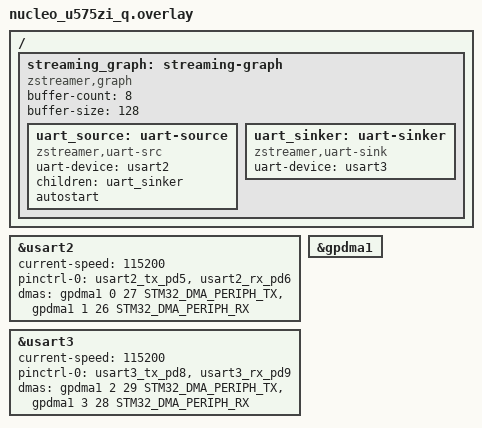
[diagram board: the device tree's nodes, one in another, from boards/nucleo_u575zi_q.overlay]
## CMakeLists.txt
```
# Copyright (c) 2026 sharonthecreator
# SPDX-License-Identifier: Apache-2.0

cmake_minimum_required(VERSION 3.20.0)
find_package(Zephyr REQUIRED HINTS $ENV{ZEPHYR_BASE})
project(uart2uart)

target_sources(app PRIVATE src/main.c)
```

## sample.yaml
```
# Copyright (c) 2026 sharonthecreator
# SPDX-License-Identifier: Apache-2.0

sample:
  name: UART-to-UART relay
  description: |
    Relays bytes received on one UART to another using a
    zstreamer graph with uart-src and uart-sink nodes.
tests:
  sample.zstreamer.uart2uart:
    tags: zstreamer uart
    platform_allow: nucleo_u575zi_q
```

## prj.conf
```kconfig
# Copyright (c) 2026 sharonthecreator
# SPDX-License-Identifier: Apache-2.0

CONFIG_ZSTREAMER=y
CONFIG_ZSTREAMER_UART_SRC=y
CONFIG_ZSTREAMER_UART_SINK=y
CONFIG_SERIAL=y
CONFIG_LOG=y
# Enable UART async/DMA API for efficient transfers
CONFIG_UART_ASYNC_API=y
CONFIG_DMA=y
```

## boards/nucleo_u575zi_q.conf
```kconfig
# Copyright (c) 2026 sharonthecreator
# SPDX-License-Identifier: Apache-2.0

# Enable UART async/DMA API for efficient transfers
CONFIG_UART_ASYNC_API=y
CONFIG_DMA=y
```

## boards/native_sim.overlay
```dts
/*
 * Copyright (c) 2026 sharonthecreator
 * SPDX-License-Identifier: Apache-2.0
 *
 * UART-to-UART relay on native_sim using emulated UARTs.
 */

/ {
	uart_src: uart-emul-src {
		compatible = "zephyr,uart-emul";
		current-speed = <115200>;
		rx-fifo-size = <256>;
		tx-fifo-size = <256>;
		status = "okay";
	};

	uart_sink: uart-emul-sink {
		compatible = "zephyr,uart-emul";
		current-speed = <115200>;
		rx-fifo-size = <256>;
		tx-fifo-size = <256>;
		status = "okay";
	};

	streaming_graph: streaming-graph {
		compatible = "zstreamer,graph";
		buffer-count = <8>;
		buffer-size = <128>;

		uart_source: uart-source {
			compatible = "zstreamer,uart-src";
			uart-device = <&uart_src>;
			children = <&uart_sinker>;
		};

		uart_sinker: uart-sinker {
			compatible = "zstreamer,uart-sink";
			uart-device = <&uart_sink>;
		};
	};
};
```

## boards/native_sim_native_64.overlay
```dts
/*
 * Copyright (c) 2026 sharonthecreator
 * SPDX-License-Identifier: Apache-2.0
 *
 * UART-to-UART relay on native_sim using emulated UARTs.
 */

/ {
	uart_src: uart-emul-src {
		compatible = "zephyr,uart-emul";
		current-speed = <115200>;
		rx-fifo-size = <256>;
		tx-fifo-size = <256>;
		status = "okay";
	};

	uart_sink: uart-emul-sink {
		compatible = "zephyr,uart-emul";
		current-speed = <115200>;
		rx-fifo-size = <256>;
		tx-fifo-size = <256>;
		status = "okay";
	};

	streaming_graph: streaming-graph {
		compatible = "zstreamer,graph";
		buffer-count = <8>;
		buffer-size = <128>;

		uart_source: uart-source {
			compatible = "zstreamer,uart-src";
			uart-device = <&uart_src>;
			children = <&uart_sinker>;
			autostart;
		};

		uart_sinker: uart-sinker {
			compatible = "zstreamer,uart-sink";
			uart-device = <&uart_sink>;
		};
	};
};
```

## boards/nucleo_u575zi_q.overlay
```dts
/*
 * Copyright (c) 2026 sharonthecreator
 * SPDX-License-Identifier: Apache-2.0
 *
 * UART-to-UART relay on Nucleo U575ZI-Q with DMA support.
 *
 * Source: USART2 (PD5 TX / PD6 RX) — Morpho CN11
 * Sink:   USART3 (PD8 TX / PD9 RX) — Morpho CN12
 *
 * Connect an external serial adapter to USART2 to send data;
 * the pipeline relays it out on USART3.
 *
 * DMA is automatically used when CONFIG_UART_ASYNC_API is enabled.
 */

&usart2 {
	status = "okay";
	current-speed = <115200>;
	pinctrl-0 = <&usart2_tx_pd5 &usart2_rx_pd6>;
	pinctrl-names = "default";
	dmas = <&gpdma1 0 27 STM32_DMA_PERIPH_TX>,
	       <&gpdma1 1 26 STM32_DMA_PERIPH_RX>;
	dma-names = "tx", "rx";
};

&usart3 {
	status = "okay";
	current-speed = <115200>;
	pinctrl-0 = <&usart3_tx_pd8 &usart3_rx_pd9>;
	pinctrl-names = "default";
	dmas = <&gpdma1 2 29 STM32_DMA_PERIPH_TX>,
	       <&gpdma1 3 28 STM32_DMA_PERIPH_RX>;
	dma-names = "tx", "rx";
};

&gpdma1 {
	status = "okay";
};

/ {
	streaming_graph: streaming-graph {
		compatible = "zstreamer,graph";
		buffer-count = <8>;
		buffer-size = <128>;

		uart_source: uart-source {
			compatible = "zstreamer,uart-src";
			uart-device = <&usart2>;
			children = <&uart_sinker>;
			autostart;
		};

		uart_sinker: uart-sinker {
			compatible = "zstreamer,uart-sink";
			uart-device = <&usart3>;
		};
	};
};
```

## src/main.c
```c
/*
 * Copyright (c) 2026 sharonthecreator
 * SPDX-License-Identifier: Apache-2.0
 */

#include <zephyr/device.h>
#include <zephyr/kernel.h>
#include <zephyr/logging/log.h>

#include <zstreamer/source.h>

LOG_MODULE_REGISTER(uart2uart, LOG_LEVEL_INF);

#define SRC_NODE DT_NODELABEL(uart_source)

int main(void) {
  const struct device *src = DEVICE_DT_GET(SRC_NODE);
  int ret;

  if (!device_is_ready(src)) {
    LOG_ERR("source device not ready");
    return -ENODEV;
  }

  ret = zstreamer_source_start(src);
  if (ret) {
    LOG_ERR("failed to start pipeline: %d", ret);
    return ret;
  }

  LOG_INF("uart2uart pipeline running");
  return 0;
}
```
